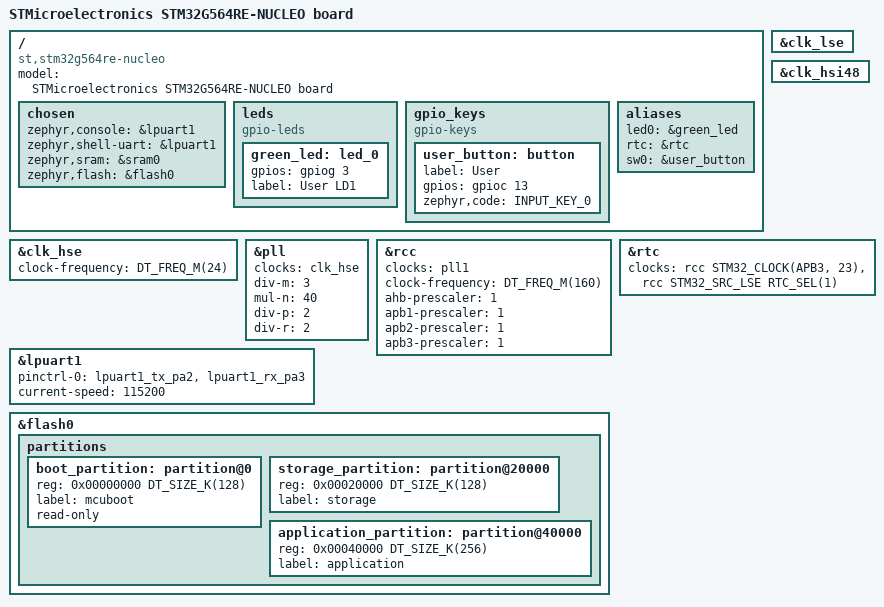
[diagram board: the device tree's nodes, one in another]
/*
 * Copyright (c) 2026 STMicroelectronics
 *
 * SPDX-License-Identifier: Apache-2.0
 */

/dts-v1/;
#include <st/g5/stm32g564Xe.dtsi>
#include <st/g5/stm32g5(5-6)4r(b-c-e)tx(u-z-_)-pinctrl.dtsi>
#include "arduino_r3_connector.dtsi"
#include "st_morpho_connector.dtsi"
#include <zephyr/dt-bindings/input/input-event-codes.h>

/ {
	compatible = "st,stm32g564re-nucleo";
	model = "STMicroelectronics STM32G564RE-NUCLEO board";

	chosen {
		zephyr,console = &lpuart1;
		zephyr,shell-uart = &lpuart1;
		zephyr,sram = &sram0;
		zephyr,flash = &flash0;
	};

	leds {
		compatible = "gpio-leds";

		green_led: led_0 {
			gpios = <&gpiog 3 GPIO_ACTIVE_HIGH>;
			label = "User LD1";
		};
	};

	gpio_keys {
		compatible = "gpio-keys";

		user_button: button {
			label = "User";
			gpios = <&gpioc 13 (GPIO_ACTIVE_HIGH | GPIO_PULL_DOWN)>;
			zephyr,code = <INPUT_KEY_0>;
		};
	};

	aliases {
		led0 = &green_led;
		rtc = &rtc;
		sw0 = &user_button;
	};
};

&clk_lse {
	status = "okay";
};

&clk_hse {
	clock-frequency = <DT_FREQ_M(24)>;
	status = "okay";
};

&clk_hsi48 {
	status = "okay";
};

&pll {
	clocks = <&clk_hse>;
	div-m = <3>;
	mul-n = <40>;
	div-p = <2>;
	div-r = <2>;
	status = "okay";
};

&rcc {
	clocks = <&pll1>;
	clock-frequency = <DT_FREQ_M(160)>;
	ahb-prescaler = <1>;
	apb1-prescaler = <1>;
	apb2-prescaler = <1>;
	apb3-prescaler = <1>;
};

&lpuart1 {
	pinctrl-0 = <&lpuart1_tx_pa2 &lpuart1_rx_pa3>;
	pinctrl-names = "default";
	current-speed = <115200>;
	status = "okay";
};

&rtc {
	clocks = <&rcc STM32_CLOCK(APB3, 23)>,
		 <&rcc STM32_SRC_LSE RTC_SEL(1)>;
	status = "okay";
};

&flash0 {
	partitions {
		ranges;
		#address-cells = <1>;
		#size-cells = <1>;

		boot_partition: partition@0 {
			reg = <0x00000000 DT_SIZE_K(128)>;
			label = "mcuboot";
			read-only;
		};

		storage_partition: partition@20000 {
			reg = <0x00020000 DT_SIZE_K(128)>;
			label = "storage";
		};

		application_partition: partition@40000 {
			reg = <0x00040000 DT_SIZE_K(256)>;
			label = "application";
		};
	};
};
